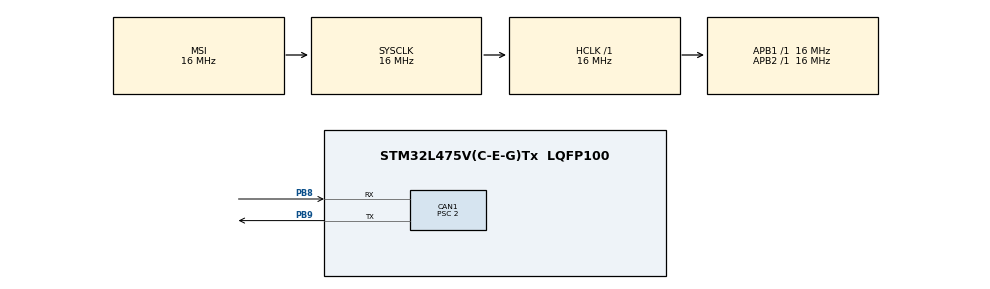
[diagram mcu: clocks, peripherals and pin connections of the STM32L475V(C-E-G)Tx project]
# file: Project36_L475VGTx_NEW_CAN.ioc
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CAN1.BS1=CAN_BS1_13TQ
CAN1.BS2=CAN_BS2_2TQ
CAN1.CalculateBaudRate=500000
CAN1.CalculateTimeBit=2000.00
CAN1.CalculateTimeQuantum=125.0
CAN1.Prescaler=2
Mcu.Family=STM32L4
Mcu.Name=STM32L475V(C-E-G)Tx
Mcu.Package=LQFP100
NVIC.CAN1_RX0_IRQn=true\:0\:0\:false\:false\:true\:true\:true
NVIC.PriorityGroup=NVIC_PRIORITYGROUP_4
PB8.Mode=CAN_Activate
PB8.Signal=CAN1_RX
PB9.Mode=CAN_Activate
PB9.Signal=CAN1_TX
PH0-OSC_IN\ (PH0).Mode=HSE-External-Oscillator
PH0-OSC_IN\ (PH0).Signal=RCC_OSC_IN
PH1-OSC_OUT\ (PH1).Mode=HSE-External-Oscillator
PH1-OSC_OUT\ (PH1).Signal=RCC_OSC_OUT
ProjectManager.HeapSize=0x200
ProjectManager.StackSize=0x400
ProjectManager.TargetToolchain=EWARM V8.32
RCC.ADCFreq_Value=64000000
RCC.AHBFreq_Value=16000000
RCC.APB1Freq_Value=16000000
RCC.APB1TimFreq_Value=16000000
RCC.APB2Freq_Value=16000000
RCC.APB2TimFreq_Value=16000000
RCC.CortexFreq_Value=16000000
RCC.HCLKFreq_Value=16000000
RCC.HSE_VALUE=8000000
RCC.HSI_VALUE=16000000
RCC.LSE_VALUE=32768
RCC.MSIClockRange=RCC_MSIRANGE_8
RCC.MSI_VALUE=16000000
RCC.SYSCLKFreq_VALUE=16000000
RCC.USBFreq_Value=64000000
RCC.VCOOutputFreq_Value=128000000
board=custom

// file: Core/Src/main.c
/* USER CODE BEGIN Header */
/**
  ******************************************************************************
  * @file           : main.c
  * @brief          : Main program body
  ******************************************************************************
  * @attention
  *
  * <h2><center>&copy; Copyright (c) 2021 STMicroelectronics.
  * All rights reserved.</center></h2>
  *
  * This software component is licensed by ST under BSD 3-Clause license,
  * the "License"; You may not use this file except in compliance with the
  * License. You may obtain a copy of the License at:
  *                        opensource.org/licenses/BSD-3-Clause
  *
  ******************************************************************************
  */
/* USER CODE END Header */
#include "main.h"

CAN_HandleTypeDef hcan1;

/* USER CODE BEGIN PV */
CAN_HandleTypeDef hcan1;
CAN_TxHeaderTypeDef pTxHeader;
CAN_RxHeaderTypeDef pRxHeader;
uint32_t pTxMailbox;
uint8_t a[]={'S', 'a', 'l', 'u', 't', 'C', 'A', '1'};
uint8_t r[8];
CAN_FilterTypeDef sFilterConfig;
/* USER CODE END PV */

void SystemClock_Config(void);
static void MX_GPIO_Init(void);
static void MX_CAN1_Init(void);

int main(void)
{

  /* MCU Configuration--------------------------------------------------------*/

  /* Reset of all peripherals, Initializes the Flash interface and the Systick. */
  HAL_Init();

  /* Configure the system clock */
  SystemClock_Config();

  /* Initialize all configured peripherals */
  MX_GPIO_Init();
  MX_CAN1_Init();
  /* USER CODE BEGIN 2 */
pTxHeader.DLC = 8;
pTxHeader.IDE = CAN_ID_STD;
pTxHeader.RTR = CAN_RTR_DATA;
pTxHeader.StdId = 0x245;

sFilterConfig.FilterFIFOAssignment = CAN_FILTER_FIFO0;
sFilterConfig.FilterIdHigh = 0;
sFilterConfig.FilterIdLow = 0;
sFilterConfig.FilterMaskIdHigh = 0;
sFilterConfig.FilterIdLow = 0;
sFilterConfig.FilterScale = CAN_FILTERSCALE_32BIT;
sFilterConfig.FilterActivation = ENABLE;

HAL_CAN_ConfigFilter(&hcan1, &sFilterConfig);

HAL_CAN_Start(&hcan1);
HAL_CAN_ActivateNotification(&hcan1, CAN_IT_RX_FIFO0_MSG_PENDING);
  /* USER CODE END 2 */

  /* Infinite loop */
  /* USER CODE BEGIN WHILE */
  while (1)
  {
    for(int i=0;i<8;i++){a[i]++;}
    HAL_CAN_AddTxMessage(&hcan1, &pTxHeader, a, &pTxMailbox);
    /* USER CODE END WHILE */

  }
}

void SystemClock_Config(void)
{
  RCC_OscInitTypeDef RCC_OscInitStruct = {0};
  RCC_ClkInitTypeDef RCC_ClkInitStruct = {0};

  /** Initializes the RCC Oscillators according to the specified parameters
  * in the RCC_OscInitTypeDef structure.
  */
  RCC_OscInitStruct.OscillatorType = RCC_OSCILLATORTYPE_MSI;
  RCC_OscInitStruct.MSIState = RCC_MSI_ON;
  RCC_OscInitStruct.MSICalibrationValue = 0;
  RCC_OscInitStruct.MSIClockRange = RCC_MSIRANGE_8;
  RCC_OscInitStruct.PLL.PLLState = RCC_PLL_NONE;
  if (HAL_RCC_OscConfig(&RCC_OscInitStruct) != HAL_OK)
  {
    Error_Handler();
  }
  /** Initializes the CPU, AHB and APB buses clocks
  */
  RCC_ClkInitStruct.ClockType = RCC_CLOCKTYPE_HCLK|RCC_CLOCKTYPE_SYSCLK
                              |RCC_CLOCKTYPE_PCLK1|RCC_CLOCKTYPE_PCLK2;
  RCC_ClkInitStruct.SYSCLKSource = RCC_SYSCLKSOURCE_MSI;
  RCC_ClkInitStruct.AHBCLKDivider = RCC_SYSCLK_DIV1;
  RCC_ClkInitStruct.APB1CLKDivider = RCC_HCLK_DIV1;
  RCC_ClkInitStruct.APB2CLKDivider = RCC_HCLK_DIV1;

  if (HAL_RCC_ClockConfig(&RCC_ClkInitStruct, FLASH_LATENCY_0) != HAL_OK)
  {
    Error_Handler();
  }
  /** Configure the main internal regulator output voltage
  */
  if (HAL_PWREx_ControlVoltageScaling(PWR_REGULATOR_VOLTAGE_SCALE1) != HAL_OK)
  {
    Error_Handler();
  }
}

static void MX_CAN1_Init(void)
{

  hcan1.Instance = CAN1;
  hcan1.Init.Prescaler = 2;
  hcan1.Init.Mode = CAN_MODE_NORMAL;
  hcan1.Init.SyncJumpWidth = CAN_SJW_1TQ;
  hcan1.Init.TimeSeg1 = CAN_BS1_13TQ;
  hcan1.Init.TimeSeg2 = CAN_BS2_2TQ;
  hcan1.Init.TimeTriggeredMode = DISABLE;
  hcan1.Init.AutoBusOff = DISABLE;
  hcan1.Init.AutoWakeUp = DISABLE;
  hcan1.Init.AutoRetransmission = DISABLE;
  hcan1.Init.ReceiveFifoLocked = DISABLE;
  hcan1.Init.TransmitFifoPriority = DISABLE;
  if (HAL_CAN_Init(&hcan1) != HAL_OK)
  {
    Error_Handler();
  }

}

static void MX_GPIO_Init(void)
{

  /* GPIO Ports Clock Enable */
  __HAL_RCC_GPIOH_CLK_ENABLE();
  __HAL_RCC_GPIOB_CLK_ENABLE();

}

void Error_Handler(void)
{
  __disable_irq();
  while (1)
  {
  }
}

/************************ (C) COPYRIGHT STMicroelectronics *****END OF FILE****/
